# f28003x_fsi_tx_regs register map
Vendor: Texas Instruments
Peripheral module from a debugger description file (folder C2000).
Address unit: 16 bits
Registers are 16-bit, read-write, no defined reset value unless marked. A register's access mark holds for its fields unless they carry their own. Offsets are as the file gives them; lines under a group give offsets from that group; [hi:lo] are bit positions; {n}, {i} and the like mark numbered series; 'fields as' and 'values as' point back to an identical list; <NAME> marks a mode.

## FSI_TX_REGS — FSI TX Registers
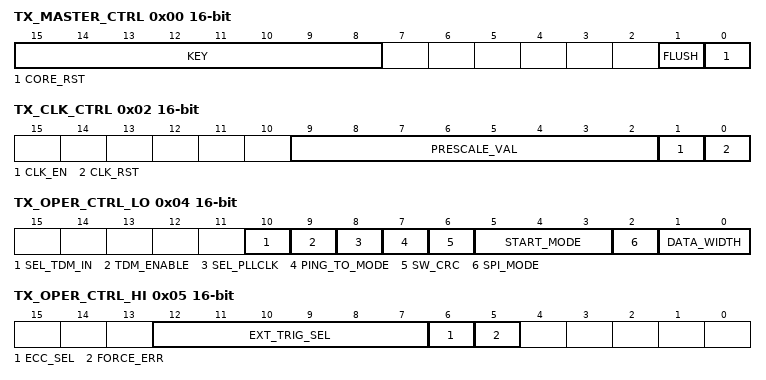
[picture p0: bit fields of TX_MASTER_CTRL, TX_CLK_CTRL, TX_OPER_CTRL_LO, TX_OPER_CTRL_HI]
0x00 TX_MASTER_CTRL — Transmit master control register
  [15:8] KEY — Write Key
  [1] FLUSH — Flush Operation Start
  [0] CORE_RST — Transmitter Master Core Reset
0x02 TX_CLK_CTRL — Transmit clock control register
  [9:2] PRESCALE_VAL — Prescale value
  [1] CLK_EN — Clock Divider Enable
  [0] CLK_RST — Soft Reset for the Clock Divider
0x04 TX_OPER_CTRL_LO — Transmit operation control register low
  [10] SEL_TDM_IN — Input TDM Port Select
  [9] TDM_ENABLE — Transmit TDM Mode Enable
  [8] SEL_PLLCLK — Input Clock Select
  [7] PING_TO_MODE — Ping Counter Reset Mode Select
  [6] SW_CRC — CRC Source Select
  [5:3] START_MODE — Transmission Start Mode Select
  [2] SPI_MODE — SPI Mode Select
  [1:0] DATA_WIDTH — Transmit Data width
0x05 TX_OPER_CTRL_HI — Transmit operation control register high
  [12:7] EXT_TRIG_SEL — External Trigger Select
  [6] ECC_SEL — ECC Data Width Select
  [5] FORCE_ERR — Error Frame Force
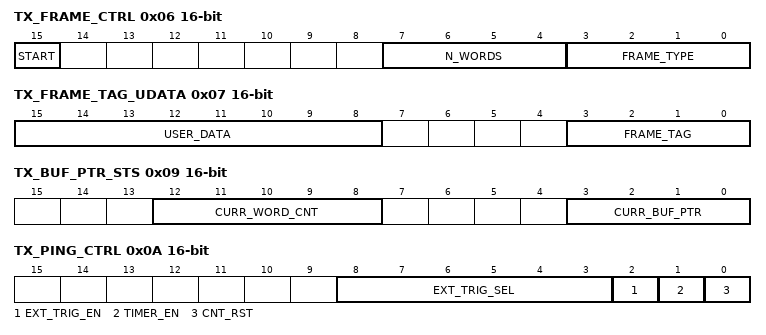
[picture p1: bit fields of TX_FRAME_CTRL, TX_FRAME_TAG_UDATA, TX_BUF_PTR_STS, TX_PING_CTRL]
0x06 TX_FRAME_CTRL — Transmit frame control register
  [15] START — Start Transmission
  [7:4] N_WORDS — Number of Words to be Transmitted
  [3:0] FRAME_TYPE — Transmit Frame Type
0x07 TX_FRAME_TAG_UDATA — Transmit frame tag and user data register
  [15:8] USER_DATA, [3:0] FRAME_TAG
0x08 TX_BUF_PTR_LOAD — Transmit buffer pointer control load register
  [3:0] BUF_PTR_LOAD — Buffer Pointer Force Load
0x09 TX_BUF_PTR_STS ro — Transmit buffer pointer control status register
  [12:8] CURR_WORD_CNT — Remaining Words in Buffer
  [3:0] CURR_BUF_PTR — Current Buffer Pointer Index
0x0A TX_PING_CTRL — Transmit ping control register
  [8:3] EXT_TRIG_SEL — External Trigger Select
  [2] EXT_TRIG_EN — External Trigger Enable
  [1] TIMER_EN — Ping Counter Enable
  [0] CNT_RST — Ping Counter Reset
0x0B TX_PING_TAG — Transmit ping tag register
  [3:0] TAG — Ping Frame Tag
0x0C TX_PING_TO_REF 32-bit — Transmit ping timeout counter reference
  [31:0] TO_REF — Ping Timer Reference
0x0E TX_PING_TO_CNT 32-bit ro — Transmit ping timeout current count
  [31:0] TO_CNT — Ping Timer Counter
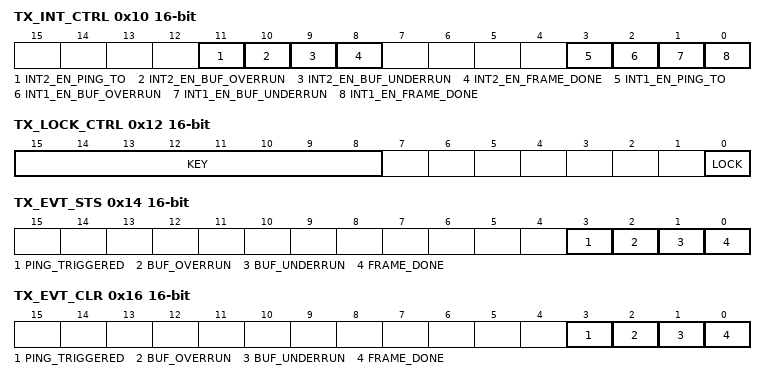
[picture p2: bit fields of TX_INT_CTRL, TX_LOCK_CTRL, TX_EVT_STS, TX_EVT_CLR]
0x10 TX_INT_CTRL — Transmit interrupt event control register
  [11] INT2_EN_PING_TO — Enable Ping Timer Interrupt to INT2
  [10] INT2_EN_BUF_OVERRUN — Enable Buffer Overrun Interrupt to INT2
  [9] INT2_EN_BUF_UNDERRUN — Enable Buffer Underrun Interrupt to INT2
  [8] INT2_EN_FRAME_DONE — Enable Frame Done Interrupt to INT2
  [3] INT1_EN_PING_TO — Enable Ping Timer Interrupt to INT1
  [2] INT1_EN_BUF_OVERRUN — Enable Buffer Overrun Interrupt to INT1
  [1] INT1_EN_BUF_UNDERRUN — Enable Buffer Underrun Interrupt to INT1
  [0] INT1_EN_FRAME_DONE — Enable Frame Done Interrupt to INT1
0x11 TX_DMA_CTRL — Transmit DMA event control register
  [0] DMA_EVT_EN — DMA Event Enable
0x12 TX_LOCK_CTRL — Transmit lock control register
  [15:8] KEY — Write Key
  [0] LOCK — Control Register Lock Enable
0x14 TX_EVT_STS ro — Transmit event and error status flag register
  [3] PING_TRIGGERED — Ping Frame Triggered Flag
  [2] BUF_OVERRUN — Buffer Overrun Flag
  [1] BUF_UNDERRUN — Buffer Underrun Flag
  [0] FRAME_DONE — Frame Done Flag
0x16 TX_EVT_CLR — Transmit event and error clear register
  [3] PING_TRIGGERED — Ping Frame Triggered Flag Clear
  [2] BUF_OVERRUN — Buffer Overrun Flag Clear
  [1] BUF_UNDERRUN — Buffer Underrun Flag Clear
  [0] FRAME_DONE — Frame Done Flag Clear
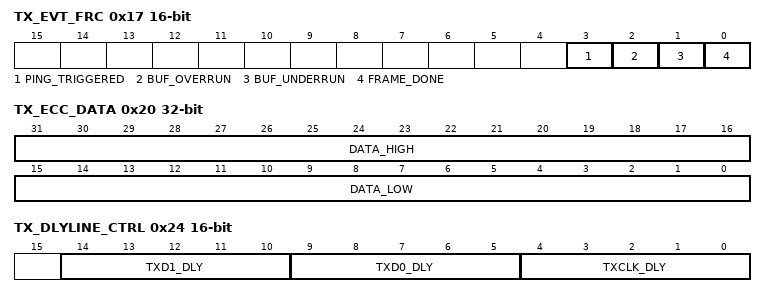
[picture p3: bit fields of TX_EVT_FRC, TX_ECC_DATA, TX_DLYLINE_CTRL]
0x17 TX_EVT_FRC — Transmit event and error flag force register
  [3] PING_TRIGGERED — Ping Frame Triggered Flag Force
  [2] BUF_OVERRUN — Buffer Overrun Flag Force
  [1] BUF_UNDERRUN — Buffer Underrun Flag Force
  [0] FRAME_DONE — Frame Done Flag Force
0x18 TX_USER_CRC — Transmit user-defined CRC register
  [7:0] USER_CRC — User-defined CRC
0x20 TX_ECC_DATA 32-bit — Transmit ECC data register
  [31:16] DATA_HIGH — ECC Data Upper 16 Bits
  [15:0] DATA_LOW — ECC Data Lower 16 Bits
0x22 TX_ECC_VAL ro — Transmit ECC value register
  [6:0] ECC_VAL — Computed ECC Value
0x24 TX_DLYLINE_CTRL — Transmit delay Line control register
  [14:10] TXD1_DLY — Delay Line Tap Select for TXD1
  [9:5] TXD0_DLY — Delay Line Tap Select for TXD0
  [4:0] TXCLK_DLY — Delay Line Tap Select for TXCLK
0x40 TX_BUF_BASE — Base address for transmit buffer
  [15:0] BASE_ADDRESS — Transmit Data Buffer Base Address
